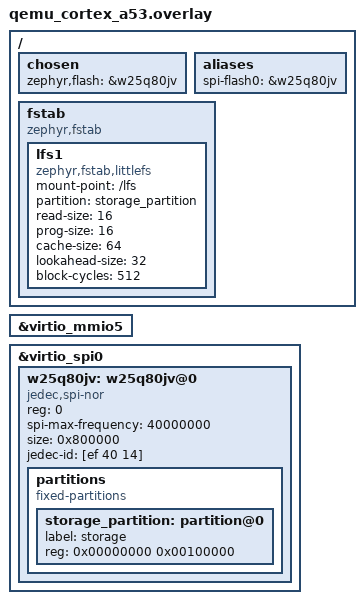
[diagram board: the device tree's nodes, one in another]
/*
 * Enable the browser SPI bridge and put a JEDEC SPI NOR on CS0. The page
 * answers as a W25Q-class part (src/virtio/devices/chips/w25q.ts); jedec-id
 * and size must match that model. Size is in *bits* (JESD216 / Zephyr binding).
 *
 * 1 MiB (density 0x14) covers samples/drivers/spi_flash's default test region
 * at offset 0xff000 plus a 4 KiB sector. The whole chip is also a LittleFS
 * "storage" partition with fstab entry lfs1 → /lfs for samples/subsys/fs/littlefs.
 * Packaged conf sets SPI_NOR_FLASH_LAYOUT_PAGE_SIZE=4096 so LFS block_size
 * matches the erase sector (stock Zephyr defaults this to 64 KiB).
 */

&virtio_mmio5 {
	status = "okay";
};

&virtio_spi0 {
	status = "okay";

	w25q80jv: w25q80jv@0 {
		compatible = "jedec,spi-nor";
		reg = <0>;
		spi-max-frequency = <40000000>;
		size = <0x800000>; /* 1 MiB */
		jedec-id = [ef 40 14];
		status = "okay";

		partitions {
			compatible = "fixed-partitions";
			#address-cells = <1>;
			#size-cells = <1>;

			storage_partition: partition@0 {
				label = "storage";
				reg = <0x00000000 0x00100000>;
			};
		};
	};
};

/ {
	chosen {
		zephyr,flash = &w25q80jv;
	};

	aliases {
		spi-flash0 = &w25q80jv;
	};

	fstab {
		compatible = "zephyr,fstab";
		lfs1: lfs1 {
			compatible = "zephyr,fstab,littlefs";
			mount-point = "/lfs";
			partition = <&storage_partition>;
			/* Sample mounts explicitly; shell can `fs mount` too. */
			read-size = <16>;
			prog-size = <16>;
			cache-size = <64>;
			lookahead-size = <32>;
			block-cycles = <512>;
		};
	};
};
